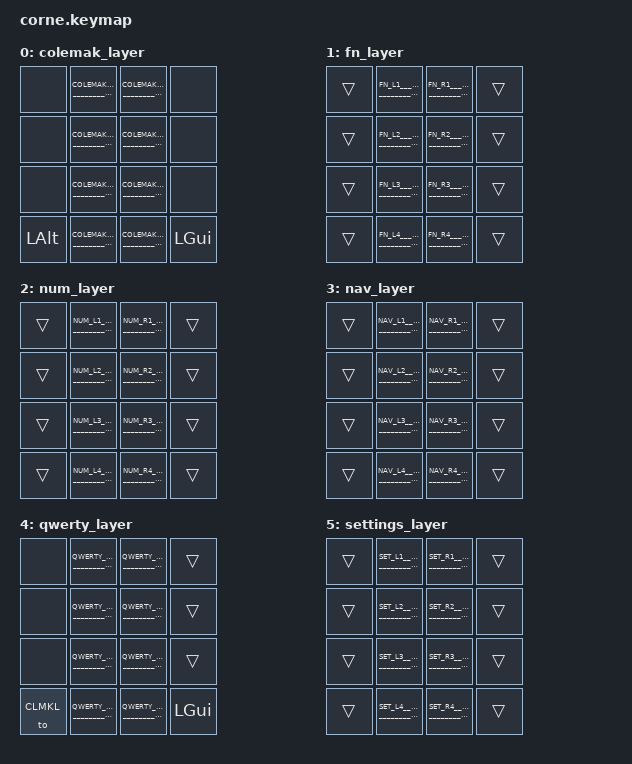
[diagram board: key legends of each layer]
// Copyrighm (c) 2022 The ZMK Contributors
// SPDX-License-Identifier: MIT

#include "../zmk-nodefree-config/keypos_def/keypos_42keys.h"

#define KEYS_L LT0 LT1 LT2 LT3 LT4 LM0 LM1 LM2 LM3 LM4 LB0 LB1 LB2 LB3 LB4
#define KEYS_R RT0 RT1 RT2 RT3 RT4 RM0 RM1 RM2 RM3 RM4 RB0 RB1 RB2 RB3 RB4
#define KEYS_T LH2 LH1 LH0 RH0 RH1 RH2

#include "core.keymap"


/ {
    conditional_layers {
        compatible = "zmk,conditional-layers";
        tri_layer {
            if-layers = <NAVL NUML>;
            then-layer = <SETL>;
        };
    };

    keymap {
        compatible = "zmk,keymap";
        colemak_layer {
            bindings = <
            &none      _____________________COLEMAK_L1_____________________  _____________________COLEMAK_R1_____________________      &none
            &none      _____________________COLEMAK_L2_____________________  _____________________COLEMAK_R2_____________________      &none
            &none      _____________________COLEMAK_L3_____________________  _____________________COLEMAK_R3_____________________      &none
            &kp LALT   _____________________COLEMAK_L4_____________________  _____________________COLEMAK_R4_____________________      &kp LGUI
            >;
        };

        fn_layer {
            bindings = <
            &trans     ________________________FN_L1_______________________  ________________________FN_R1_______________________      &trans
            &trans     ________________________FN_L2_______________________  ________________________FN_R2_______________________      &trans
            &trans     ________________________FN_L3_______________________  ________________________FN_R3_______________________      &trans
            &trans     ________________________FN_L4_______________________  ________________________FN_R4_______________________      &trans
            >;
        };

        num_layer {
            bindings = <
            &trans      _______________________NUM_L1_______________________  _______________________NUM_R1_______________________     &trans
            &trans      _______________________NUM_L2_______________________  _______________________NUM_R2_______________________     &trans
            &trans      _______________________NUM_L3_______________________  _______________________NUM_R3_______________________     &trans
            &trans      _______________________NUM_L4_______________________  _______________________NUM_R4_______________________     &trans
            >;
        };

        nav_layer {
            bindings = <
            &trans      _______________________NAV_L1_______________________  _______________________NAV_R1_______________________      &trans
            &trans      _______________________NAV_L2_______________________  _______________________NAV_R2_______________________      &trans
            &trans      _______________________NAV_L3_______________________  _______________________NAV_R3_______________________      &trans
            &trans      _______________________NAV_L4_______________________  _______________________NAV_R4_______________________      &trans
            >;
        };

        qwerty_layer {
            bindings = <
            &none      ______________________QWERTY_L1_____________________  ______________________QWERTY_R1_____________________      &trans
            &none      ______________________QWERTY_L2_____________________  ______________________QWERTY_R2_____________________      &trans
            &none      ______________________QWERTY_L3_____________________  ______________________QWERTY_R3_____________________      &trans
            &to CLMKL  ______________________QWERTY_L4_____________________  ______________________QWERTY_R4_____________________      &kp LGUI
            >;
        };

        settings_layer {
            bindings = <
            &trans      _______________________SET_L1_______________________  _______________________SET_R1_______________________      &trans
            &trans      _______________________SET_L2_______________________  _______________________SET_R2_______________________      &trans
            &trans      _______________________SET_L3_______________________  _______________________SET_R3_______________________      &trans
            &trans      _______________________SET_L4_______________________  _______________________SET_R4_______________________      &trans
            >;
        };
    };
};
